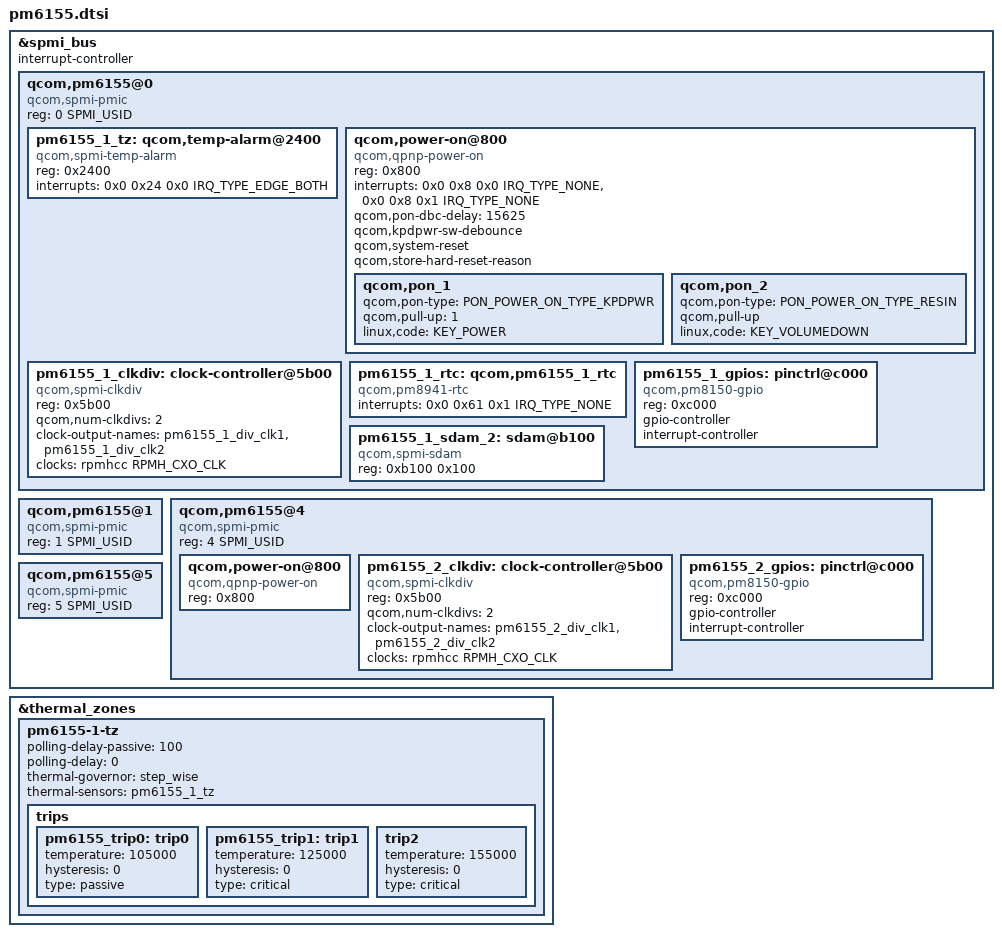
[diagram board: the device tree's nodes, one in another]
#include <dt-bindings/clock/qcom,rpmh.h>
#include <dt-bindings/input/input.h>
#include <dt-bindings/input/qcom,qpnp-power-on.h>
#include <dt-bindings/interrupt-controller/irq.h>
#include <dt-bindings/spmi/spmi.h>
#include <dt-bindings/iio/qcom,spmi-vadc.h>

&spmi_bus {
	#address-cells = <2>;
	#size-cells = <0>;
	interrupt-controller;
	#interrupt-cells = <4>;

	qcom,pm6155@0 {
		compatible = "qcom,spmi-pmic";
		reg = <0 SPMI_USID>;
		#address-cells = <1>;
		#size-cells = <0>;

		pm6155_1_tz: qcom,temp-alarm@2400 {
			compatible = "qcom,spmi-temp-alarm";
			reg = <0x2400>;
			interrupts = <0x0 0x24 0x0 IRQ_TYPE_EDGE_BOTH>;
			#thermal-sensor-cells = <0>;
		};

		qcom,power-on@800 {
			compatible = "qcom,qpnp-power-on";
			reg = <0x800>;
			interrupts = <0x0 0x8 0x0 IRQ_TYPE_NONE>,
				     <0x0 0x8 0x1 IRQ_TYPE_NONE>;
			interrupt-names = "kpdpwr", "resin";
			qcom,pon-dbc-delay = <15625>;
			qcom,kpdpwr-sw-debounce;
			qcom,system-reset;
			qcom,store-hard-reset-reason;

			qcom,pon_1 {
				qcom,pon-type = <PON_POWER_ON_TYPE_KPDPWR>;
				qcom,pull-up = <1>;
				linux,code = <KEY_POWER>;
			};

			qcom,pon_2 {
				qcom,pon-type = <PON_POWER_ON_TYPE_RESIN>;
				qcom,pull-up;
				linux,code = <KEY_VOLUMEDOWN>;
			};
		};

		pm6155_1_clkdiv: clock-controller@5b00 {
			compatible = "qcom,spmi-clkdiv";
			reg = <0x5b00>;
			#clock-cells = <1>;
			qcom,num-clkdivs = <2>;
			clock-output-names = "pm6155_1_div_clk1",
						"pm6155_1_div_clk2";
			clocks = <&rpmhcc RPMH_CXO_CLK>;
			clock-names = "xo";
		};

		pm6155_1_rtc: qcom,pm6155_1_rtc {
			compatible = "qcom,pm8941-rtc";
			interrupts = <0x0 0x61 0x1 IRQ_TYPE_NONE>;
		};

		pm6155_1_gpios: pinctrl@c000 {
			compatible = "qcom,pm8150-gpio";
			reg = <0xc000>;
			gpio-controller;
			#gpio-cells = <2>;
			interrupt-controller;
			#interrupt-cells = <2>;
		};

		pm6155_1_sdam_2: sdam@b100 {
			compatible = "qcom,spmi-sdam";
			reg = <0xb100 0x100>;
		};

	};

	qcom,pm6155@1 {
		compatible ="qcom,spmi-pmic";
		reg = <1 SPMI_USID>;
		#address-cells = <1>;
		#size-cells = <0>;
	};

	/* below definitions are for the second instance of pm6155 */
	qcom,pm6155@4 {
		compatible = "qcom,spmi-pmic";
		reg = <4 SPMI_USID>;
		#address-cells = <1>;
		#size-cells = <0>;

		qcom,power-on@800 {
			compatible = "qcom,qpnp-power-on";
			reg = <0x800>;
		};

		pm6155_2_clkdiv: clock-controller@5b00 {
			compatible = "qcom,spmi-clkdiv";
			reg = <0x5b00>;
			#clock-cells = <1>;
			qcom,num-clkdivs = <2>;
			clock-output-names = "pm6155_2_div_clk1",
						"pm6155_2_div_clk2";
			clocks = <&rpmhcc RPMH_CXO_CLK>;
			clock-names = "xo";
		};

		pm6155_2_gpios: pinctrl@c000 {
			compatible = "qcom,pm8150-gpio";
			reg = <0xc000>;
			gpio-controller;
			#gpio-cells = <2>;
			interrupt-controller;
			#interrupt-cells = <2>;
		};
	};

	qcom,pm6155@5 {
		compatible ="qcom,spmi-pmic";
		reg = <5 SPMI_USID>;
		#address-cells = <1>;
		#size-cells = <0>;
	};
};

&thermal_zones {
	pm6155-1-tz {
		polling-delay-passive = <100>;
		polling-delay = <0>;
		thermal-governor = "step_wise";
		thermal-sensors = <&pm6155_1_tz>;

		trips {
			pm6155_trip0: trip0 {
				temperature = <105000>;
				hysteresis = <0>;
				type = "passive";
			};

			pm6155_trip1: trip1 {
				temperature = <125000>;
				hysteresis = <0>;
				type = "critical";
			};

			trip2 {
				temperature = <155000>;
				hysteresis = <0>;
				type = "critical";
			};
		};
	};
};
